# KBD register map
Vendor: Texas Instruments
Peripheral module from a debugger description file (folder am571x).
Registers are 32-bit, access per field, reset 0x0 unless marked. A register's access mark holds for its fields unless they carry their own. Offsets are as the file gives them; lines under a group give offsets from that group; [hi:lo] are bit positions; {n}, {i} and the like mark numbered series; 'fields as' and 'values as' point back to an identical list; <NAME> marks a mode.

## KBD
0x00 KBD_REVISION ro reset 0x1 — This register contains the IP revision code. A write to this register has no effect.
  [31:0] Reserved — IP Revision
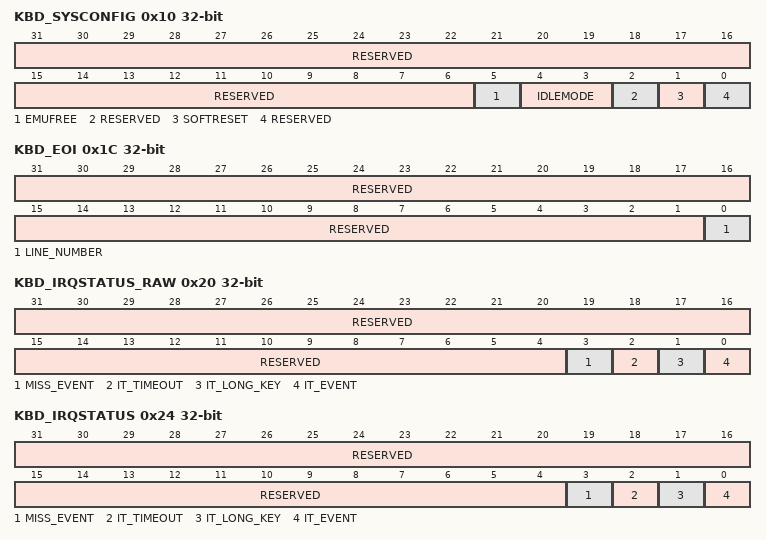
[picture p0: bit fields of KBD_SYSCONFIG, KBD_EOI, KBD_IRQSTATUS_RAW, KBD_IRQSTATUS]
0x10 KBD_SYSCONFIG — This register controls the various parameters of the OCP interface
  [31:6] RESERVED ro — Reads return 0.
  [5] EMUFREE rw — Emulation mode
    0=module_frozen (The KBDOCP module is frozen in emulation mode (PINSUSPENDN signal active).); 1=module_free (The KBDOCP module runs free, regardless of PINSUSPENDN value.)
  [4:3] IDLEMODE rw — Power Management, req/ack control
    0=Force-idle. An idle request is acknowledged unconditionally.; 1=No-idle. An idle request is never acknowledged.; 2=Smart-idle. Acknowledgement to an idle request is given based on the internal activity of the module.
  [2] RESERVED ro — Reads return 0.
  [1] SOFTRESET rw — Software reset. Write: initiate software reset Read: Reset done (0) / Reset ongoing (1)
    0=normal_mode; 1=reset_mode (The module is reset)
  [0] RESERVED ro — Reads return 0.
0x1C KBD_EOI — Software End-Of-Interrupt: Allows the generation of further pulses on the interrupt line, if an new interrupt event is pending, when using the pulsed output. Unused when using the level interrupt line (depending on module integration).
  [31:1] RESERVED ro — Reads return 0.
  [0] LINE_NUMBER rw — Software End Of Interrupt (EOI) control. Write number of interrupt output.
    0=IT_EVENT_0 (No event.); 1=IT_EVENT_1 (An event occurs.)
0x20 KBD_IRQSTATUS_RAW — Per-event raw interrupt status vector Raw status is set even if event is not enabled. Write 1 to set the (raw) status, mostly for debug.
  [31:4] RESERVED ro — Reads return 0
  [3] MISS_EVENT rw — IRQ status for Miss event Read 0 : No event pending Write 0 : No action Read 1 : IRQ event pending Write 1 : Trigger IRQ event by software
  [2] IT_TIMEOUT rw — IRQ status for Timeout Read 0 : No event pending Write 0 : No action Read 1 : IRQ event pending Write 1 : Trigger IRQ event by software
  [1] IT_LONG_KEY rw — IRQ status for Long key Read 0 : No event pending Write 0 : No action Read 1 : IRQ event pending Write 1 : Trigger IRQ event by software
  [0] IT_EVENT rw — IRQ status for Event Read 0 : No event pending Write 0 : No action Read 1 : IRQ event pending Write 1 : Trigger IRQ event by software
0x24 KBD_IRQSTATUS — Per-event 'enabled' interrupt status vector. Enabled status isn't set unless event is enabled. Write 1 to clear the status after interrupt has been serviced (raw status gets cleared, i.e. even if not enabled).
  [31:4] RESERVED ro — Reads return 0
  [3] MISS_EVENT rw — IRQ status for Miss event Read always returns zero Write 0 : No action Write 1 : Clear pending event, if any
  [2] IT_TIMEOUT rw — IRQ status for Timeout Read 0 : No event pending Write 0 : No action Read 1 : IRQ event pending Write 1 : Clear pending event, if any
  [1] IT_LONG_KEY rw — IRQ status for Long key Read 0 : No event pending Write 0 : No action Read 1 : IRQ event pending Write 1 : Clear pending event, if any
  [0] IT_EVENT rw — IRQ status for Event Read 0 : No event pending Write 0 : No action Read 1 : IRQ event pending Write 1 : Clear pending event, if any
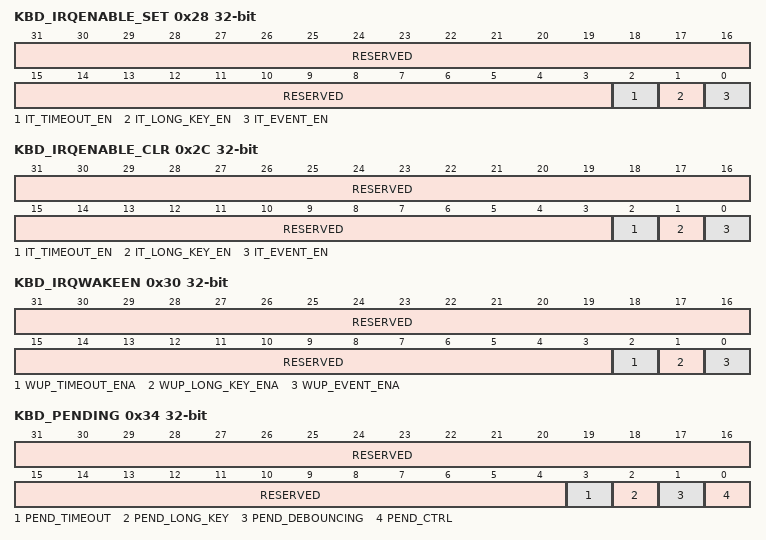
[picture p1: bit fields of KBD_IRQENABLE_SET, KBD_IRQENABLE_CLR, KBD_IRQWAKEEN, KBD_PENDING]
0x28 KBD_IRQENABLE_SET — Per-event interrupt enable bit vector Write 1 to set (enable interrupt). Readout equal to corresponding _CLR register.
  [31:3] RESERVED ro — Reads return 0
  [2] IT_TIMEOUT_EN rw — IRQ enable for Timeout Read 0 : IRQ event is disabled Write 0 : No action Read 1 : IRQ event is enabled Write 1 : Set IRQ enable
  [1] IT_LONG_KEY_EN rw — IRQ enable for Long key Read 0 : IRQ event is disabled Write 0 : No action Read 1 : IRQ event is enabled Write 1 : Set IRQ enable
  [0] IT_EVENT_EN rw — IRQ enable for Event Read 0 : IRQ event is disabled Write 0 : No action Read 1 : IRQ event is enabled Write 1 : Set IRQ enable
0x2C KBD_IRQENABLE_CLR — Per-event interrupt enable bit vector Write 1 to clear (disable interrupt). Readout equal to corresponding _SET register.
  [31:3] RESERVED ro — Reads return 0
  [2] IT_TIMEOUT_EN rw — IRQ enable for Timeout Read 0 : IRQ event is disabled Write 0 : No action Read 1 : IRQ event is enabled Write 1 : Clear IRQ enable
  [1] IT_LONG_KEY_EN rw — IRQ enable for Long key Read 0 : IRQ event is disabled Write 0 : No action Read 1 : IRQ event is enabled Write 1 : Clear IRQ enable
  [0] IT_EVENT_EN rw — IRQ enable for Event Read 0 : IRQ event is disabled Write 0 : No action Read 1 : IRQ event is enabled Write 1 : Clear IRQ enable
0x30 KBD_IRQWAKEEN — The Keyboard Wake-up Enable Register allows the user to mask the expected source of wake-up event that will generate a wake-up request. The is programmed synchronously with the interface clock before any idle mode request comes from the host processor.
  [31:3] RESERVED ro — Reads return 0.
  [2] WUP_TIMEOUT_ENA rw — Timeout wakeup enable.
    0=Timeout wakeup generation disabled; 1=Timeout wakeup generation enabled
  [1] WUP_LONG_KEY_ENA rw — Long key wakeup enable.
    0=Long key wakeup generation disabled; 1=Long key wakeup generation enabled
  [0] WUP_EVENT_ENA rw — Event wakeup enable.
    0=Event wakeup generation disabled; 1=Event wakeup generation enabled
0x34 KBD_PENDING ro — The software must read the pending write bits to insure that following write access will not be discarded due to on going write synchronization process. These bits are automatically cleared by internal logic when the write to the corresponding register is acknowledged.
  [31:4] RESERVED — Reads return 0.
  [3] PEND_TIMEOUT — Write pending bit forKBD_TIMEOUT register
    1=A write is pending to the register; 0=No write pending to the register
  [2] PEND_LONG_KEY — Write pending bit forKBD_KEYLONGTIME register
    1=PEND_LONGKEY_1 (A write is pending to the register); 0=PEND_LONGKEY_0 (No write pending to the register)
  [1] PEND_DEBOUNCING — Write pending bit forKBD_DEBOUNCINGTIME register
    values as PEND_TIMEOUT
  [0] PEND_CTRL — Write pending bit forKBD_CTRL register
    values as PEND_TIMEOUT
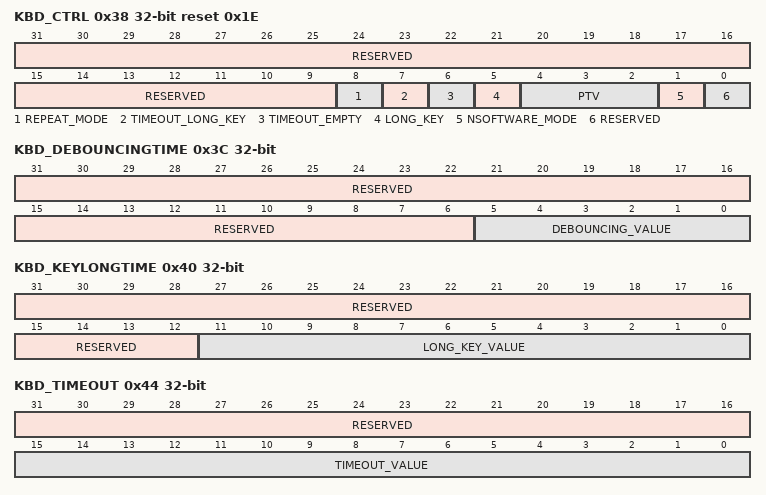
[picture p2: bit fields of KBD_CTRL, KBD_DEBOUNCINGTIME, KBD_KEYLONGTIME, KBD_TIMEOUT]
0x38 KBD_CTRL reset 0x1E — This register sets the functional configuration of the module.
  [31:9] RESERVED ro — Reads return 0.
  [8] REPEAT_MODE rw — Repeat mode enable.
    0=Repeat mode detection disabled; 1=Repeat mode detection enabled
  [7] TIMEOUT_LONG_KEY rw — Timeout long key mode enable.
    0=Timeout long key mode disabled; 1=Timeout long key mode enabled
  [6] TIMEOUT_EMPTY rw — Timeout empty mode enable.
    values as TIMEOUT_LONG_KEY
  [5] LONG_KEY rw — Long key mode enable.
    0=Long key mode disabled; 1=Long key mode enabled
  [4:2] PTV rw — Pre-scale clock timer value.
  [1] NSOFTWARE_MODE rw — Select hardware or software mode for key decoding.
    0=Enable software mode; 1=Enable hardware decoding using internal sequencer
  [0] RESERVED ro — Reads return 0.
0x3C KBD_DEBOUNCINGTIME — This register is used to filter glitches on the press key or release key.
  [31:6] RESERVED ro — Reads return 0.
  [5:0] DEBOUNCING_VALUE rw — This value correspond to the desired value of debouncing time.
0x40 KBD_KEYLONGTIME — This register is used to measure duration of a key press, to allow, shortcut detection.
  [31:12] RESERVED ro — Reads return 0.
  [11:0] LONG_KEY_VALUE rw — This value correspond to the desired value of the long key interrupt or repeat mode value.
0x44 KBD_TIMEOUT — This register is used to detect a long inactivity on the keyboard.
  [31:16] RESERVED ro — Reads return 0.
  [15:0] TIMEOUT_VALUE rw — This value correspond to the desired value of the time out interrupt.
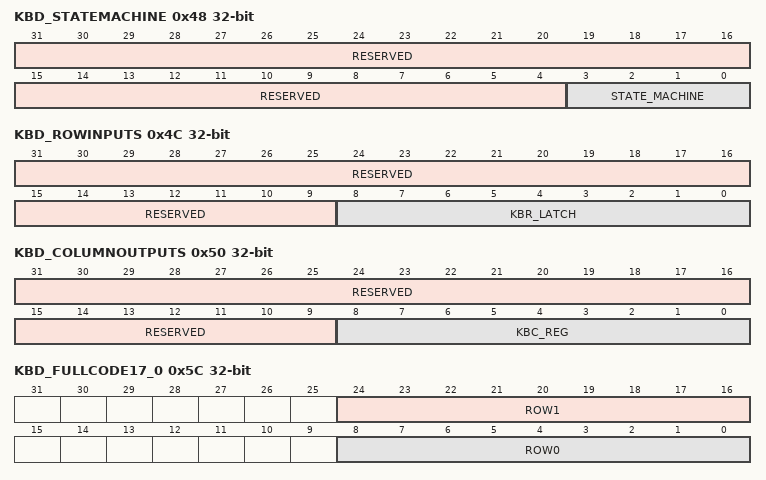
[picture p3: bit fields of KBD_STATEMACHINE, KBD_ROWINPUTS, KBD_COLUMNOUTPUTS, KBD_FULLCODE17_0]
0x48 KBD_STATEMACHINE ro — This register indicates the state of the sequencer.
  [31:4] RESERVED — Reads return 0
  [3:0] STATE_MACHINE — The state of internal state machine.
0x4C KBD_ROWINPUTS ro — This register stores the value of the rows input.
  [31:9] RESERVED — Reads return 0.
  [8:0] KBR_LATCH — The value of the rows input.
0x50 KBD_COLUMNOUTPUTS — This register holds the value of the columns output.
  [31:9] RESERVED ro — Reads return 0.
  [8:0] KBC_REG rw — The value of the columns output.
0x54 KBD_FULLCODE31_0 ro — The register codes the row 0, row 1, row 2 and row 3
  [31:0] FULL_CODE_31_0 — A bit at one indicate that the corresponding key is pressed.
0x58 KBD_FULLCODE63_32 ro — The register codes the row 4, row 5, row 6 and row 7.
  [31:0] FULL_CODE_63_32 — A bit at one indicate that the corresponding key is pressed.
0x5C KBD_FULLCODE17_0 ro — The register codes the row 0 and row 1. The row 0 is coded between bit 0 and 8, the row 1 is coded between bit 24 and
  [24:16] ROW1 — A bit at one indicate that the corresponding key is pressed.
  [8:0] ROW0 — A bit at one indicate that the corresponding key is pressed.
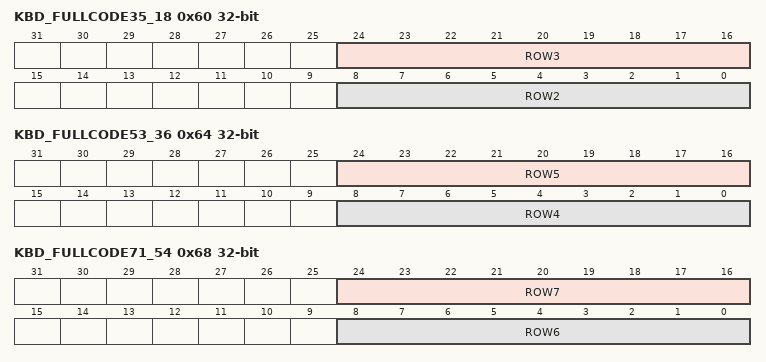
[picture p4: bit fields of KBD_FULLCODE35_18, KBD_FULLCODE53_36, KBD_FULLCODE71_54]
0x60 KBD_FULLCODE35_18 ro — The register codes the row 2 and row 3. The row 2 is coded between bit 0 and 8, the row 3 is coded between bit 24 and 16
  [24:16] ROW3 — A bit at one indicate that the corresponding key is pressed.
  [8:0] ROW2 — A bit at one indicate that the corresponding key is pressed.
0x64 KBD_FULLCODE53_36 ro — The register codes the row 4 and row 5. The row 4 is coded between bit 0 and 8, the row 5 is coded between bit 24 and 16.
  [24:16] ROW5 — A bit at one indicate that the corresponding key is pressed.
  [8:0] ROW4 — A bit at one indicate that the corresponding key is pressed.
0x68 KBD_FULLCODE71_54 ro — The register codes the row 6 and row 7. The row 0 is coded between bit 0 and 8, the row 1 is coded between bit 24 and 16
  [24:16] ROW7 — A bit at one indicate that the corresponding key is pressed.
  [8:0] ROW6 — A bit at one indicate that the corresponding key is pressed.
0x6C KBD_FULLCODE80_72 ro — The register codes the row 8. The row 8 is coded between bit 0 and 8.
  [8:0] ROW8 — A bit at one indicate that the corresponding key is pressed.
